# MAX32550 register map
Vendor: Maxim Integrated; File version: 1.0
Registers are 32-bit, read-write, reset 0x0 unless marked. A register's access mark holds for its fields unless they carry their own. Offsets are from the block's base; [hi:lo] are bit positions; {n}, {i} and the like mark numbered series; 'fields as' and 'values as' point back to an identical list.

## TFTController — Color LCD Controller
Base 0x40031000; register names take the prefix CLDC_
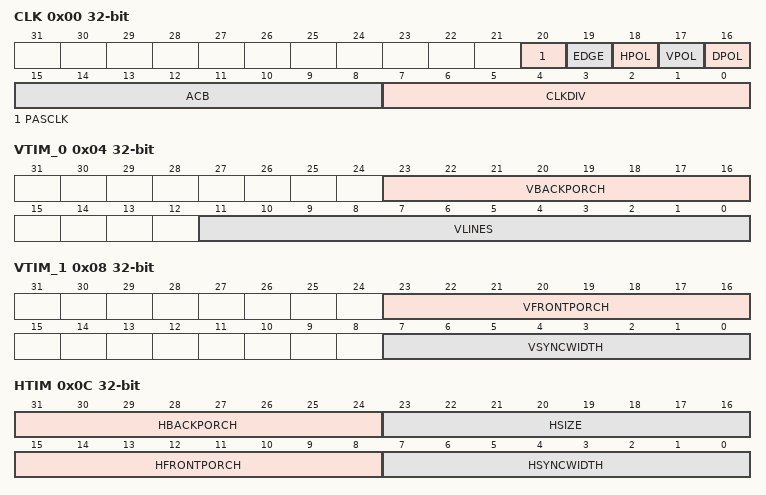
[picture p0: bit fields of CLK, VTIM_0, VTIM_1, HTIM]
0x00 CLK — LCD Clock Register
  [20] PASCLK — Passive Clock (for STN, set to 0 for TFT)
    0=alwaysActive; 1=activeOnData
  [19] EDGE — Clock Edge Select
    0=posEdge; 1=negEdge
  [18] HPOL — Horizontal Sync Polarity
    0=activeLo; 1=activeHi
  [17] VPOL — Vertical Sync Polarity
    0=activeHi; 1=activeLo
  [16] DPOL — Video Enable polarity
    0=activeHi; 1=activeLo
  [15:8] ACB — AC Bias frequency. AC bias pin toggles when the specified ACB +1 number of line clocks are applied (this field is ignored in TFT mode)
  [7:0] CLKDIV — LCD Clock Divide Value. Pixel clock frequency is PClk divided by (CLKDIV +1)
0x04 VTIM_0 — LCD Vertical Timing 0 Register
  [23:16] VBACKPORCH — Vertical Back Porch Lines
  [11:0] VLINES — Vertical Lines. Actual number of lines is 1 + register contents.
0x08 VTIM_1 — LCD Vertical Timing 1 Register
  [23:16] VFRONTPORCH — Vertical Front Porch Lines
  [7:0] VSYNCWIDTH — Vertical Sync Width. Actual number of lines is 1 + register contents.
0x0C HTIM — LCD Horizontal Timing Register
  [31:24] HBACKPORCH — Horizontal back porch in LCD clocks. Actual number of clocks is 1 + register contents.
  [23:16] HSIZE — Horizontal Size (Pixels). Actual number of pixels is 16 x (1 + register contents).
  [15:8] HFRONTPORCH — Horizontal front porch in LCD clocks. Actual number of clocks is 1 + register contents.
  [7:0] HSYNCWIDTH — Horizontal Sync Width. Actual number of clocks is 1 + register contents.
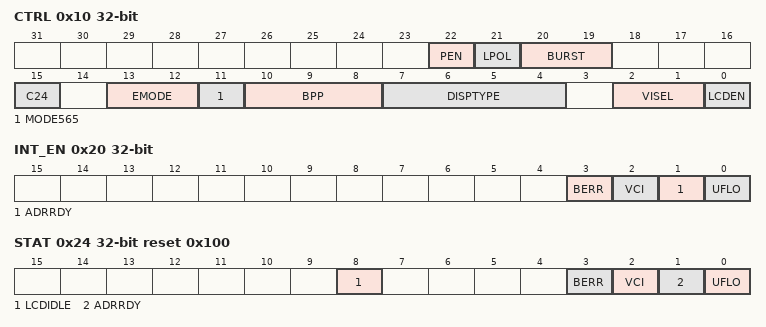
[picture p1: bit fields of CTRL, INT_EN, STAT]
0x10 CTRL — LCD Control Register
  [22] PEN — Power Enable to the panel
    0=disable; 1=enable
  [21] LPOL — LEND (Line End) Polarity
    0=activeHi; 1=activeLo
  [20:19] BURST — Threshold and Burst Size Select
    0=words4 (FIFO burst size = 4 words); 1=words8 (FIFO burst size = 8 words); other=words16 (FIFO burst size = 16 words)
  [15] C24 — Compact 24 bit. This bit changes the TFT 24 bit color mode to compact display data storage. When set to one, each word contains 1 1/3 pixels of information. When 0 only the three bytes of the word are used for LCD data.
    0=disable; 1=enable
  [13:12] EMODE — Endian Mode
    0=llbp; 1=bbbp; 2=lbbp
  [11] MODE565 — 5:6:5 Mode Select
    0=mode555 (5:5:5 Mode Select); 1=mode565 (5:6:5 Mode Select ( available from B1))
  [10:8] BPP — Bits per pixel
    0=1 bit per pixel; 1=2 bits per pixel; 2=4 bits per pixel; 3=8 bits per pixel; 4=16 bits per pixel; 5=24 bits per pixel
  [7:4] DISPTYPE — Display Type
    4=stnColor8Bit; 8=tft
  [2:1] VISEL — Vertical Compare Interrupt select
    0=onVertSync (VCI on start of vertical sync); 1=onVertBackPorch (VCI on start of vertical back porch); 2=onActiveVideo (VCI on start of active video); 3=onVertFrontPorch (VCI on start of vertical front porch)
  [0] LCDEN — LCD Enable
    0=disable; 1=enable
{0x18+4i} FRBUF_{i} (i=0..1) — Frame Buffer Address. This address points to the start of the frame Buffer. This address is always word aligned and bits 1:0 are ignored.
0x20 INT_EN — LCD Interrupt Enable Register
  [3] BERR — Bus Error interrupt enable
  [2] VCI — Vertical control interrupt enable
  [1] ADRRDY — Address ready interrupt enable
  [0] UFLO — FIFO underflow interrupt enable
0x24 STAT reset 0x100 — LCD Status Register
  [8] LCDIDLE — LCD Idle. This bit can be read after the LCD enable bit is cleared to determine when the current frame is complete.
    0=busy (Result not ready); 1=ready (Operation complete and result ready)
  [3] BERR ro write-1-clears — Bus Error interrupt
    on read: 0=inactive (No interrupt is pending.); 1=pending (An interrupt is pending.) | on write: 1=clear
  [2] VCI ro write-1-clears — Vertical control interrupt
    values as BERR
  [1] ADRRDY ro write-1-clears — Address ready interrupt
    values as BERR
  [0] UFLO ro write-1-clears — FIFO underflow interrupt
    values as BERR
0x30 HV_PHASE 8-bit — HSYNC-VSYNC Phase Difference in number of pixel clocks
